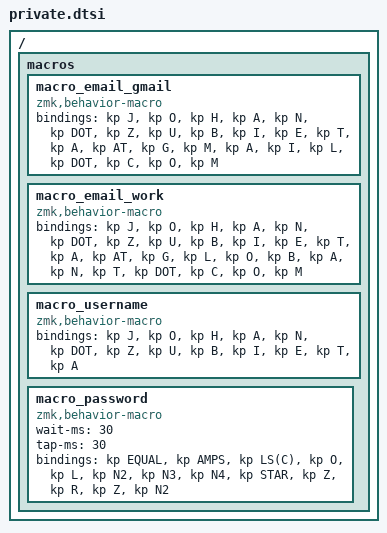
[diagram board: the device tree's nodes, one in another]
// ─────────────────────────────────────────────────────────────────────────────
// private.dtsi — Macros con datos personales
//
// Este archivo contiene placeholders para que el CI compile correctamente.
// Para usar tus datos reales localmente:
//   1. Edita este archivo con tus datos (ver private.dtsi.example)
//   2. Ejecuta: git update-index --assume-unchanged config/private.dtsi
//      (git ignorará los cambios locales sin necesidad de .gitignore)
// ─────────────────────────────────────────────────────────────────────────────

/ {
    macros {
        // Email personal (combo: A+S+D+F)
        macro_email_gmail: macro_email_gmail {
            compatible = "zmk,behavior-macro";
            #binding-cells = <0>;
            bindings = <&kp J &kp O &kp H &kp A &kp N &kp DOT &kp Z &kp U &kp B &kp I &kp E &kp T &kp A &kp AT &kp G &kp M &kp A &kp I &kp L &kp DOT &kp C &kp O &kp M>;
        };

        // Email trabajo (combo: H+J+K+L)
        macro_email_work: macro_email_work {
            compatible = "zmk,behavior-macro";
            #binding-cells = <0>;
            bindings = <&kp J &kp O &kp H &kp A &kp N &kp DOT &kp Z &kp U &kp B &kp I &kp E &kp T &kp A &kp AT &kp G &kp L &kp O &kp B &kp A &kp N &kp T &kp DOT &kp C &kp O &kp M>;
        };

        // Username (combo: R+U+S)
        macro_username: macro_username {
            compatible = "zmk,behavior-macro";
            #binding-cells = <0>;
            bindings = <&kp J &kp O &kp H &kp A &kp N &kp DOT &kp Z &kp U &kp B &kp I &kp E &kp T &kp A>;
        };

        // Password (combo: W+P)
        macro_password: macro_password {
            compatible = "zmk,behavior-macro";
            #binding-cells = <0>;
            wait-ms = <30>;
            tap-ms = <30>;
            bindings = <&kp EQUAL &kp AMPS &kp LS(C) &kp O &kp L &kp N2 &kp N3 &kp N4 &kp STAR &kp Z &kp R &kp Z &kp N2>;
        };
    };
};
